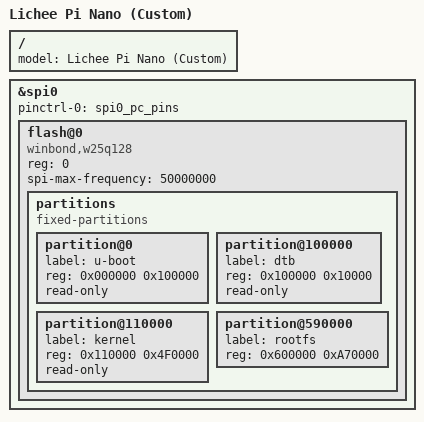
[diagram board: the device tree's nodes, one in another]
// SPDX-License-Identifier: (GPL-2.0+ OR X11)
/*
 * Copyright 2024 Pato Diaz <padiazg@gmail.com>
 *                          <patricio@patodiaz.io>
 */

/ {
	model = "Lichee Pi Nano (Custom)";
};

&spi0 {
	pinctrl-names = "default";
	pinctrl-0 = <&spi0_pc_pins>;
	status = "okay";

	flash@0 {
		#address-cells = <1>;
		#size-cells = <1>;
		compatible = "winbond,w25q128", "jedec,spi-nor";
		reg = <0>;
		spi-max-frequency = <50000000>;
        partitions {
            compatible = "fixed-partitions";
            #address-cells = <1>;
            #size-cells = <1>;

            partition@0 {
                label = "u-boot";
                reg = <0x000000 0x100000>;
                read-only;
            };

            partition@100000 {
                label = "dtb";
                reg = <0x100000 0x10000>;
                read-only;
            };

            partition@110000 {
                label = "kernel";
                reg = <0x110000 0x4F0000>;
                read-only;
            };

            partition@590000 {
                label = "rootfs";
                reg = <0x600000 0xA70000>;
            };
        };
	};
};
